AUTOSAR XML (schema 4-2-2)
package /ComponentTypes
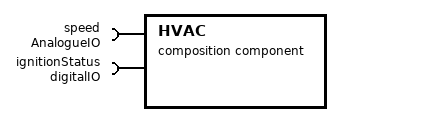
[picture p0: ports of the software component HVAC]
  composition sw component type HVAC
    require port speed: required-interface=AnalogueIO
    require port ignitionStatus: required-interface=digitalIO
    29 x component:
      SAFace: type=Switch
      SAFoot: type=Switch
      SAWindow: type=Switch
      SAHeatedDriverSeats: type=HeatedSeats
      SAHeatedPassengerSeats: type=HeatedSeats
      SAHotColdDriver: type=AirMixOut
      SAHotColdPassenger: type=AirMixOut
      SAFaceFoot: type=AirMixOut
      SAFaceVent: type=AirMixOut
      SABlowerMotorSpeed: type=AirBlowOut
      SAPassengerCurrentTempSet: type=CabinTempClosedLoop
      ECU: type=ECU
      SAOutsideTemp: type=Temp
      SADriverCabinTempSet: type=CabinTempClosedLoop
      SAAirBlower: type=AirBlow
      SAOutsideTempOutside: type=TempOut
      SAHeatedDriverSeatsOut: type=HeatedSeatsOut
      SAHeatedPassengerSeatOut: type=HeatedSeatsOut
      faceDir: type=SwitchOut
      windowDir: type=SwitchOut
      footDir: type=SwitchOut
      HotColdDriver: type=AirMixIn
      HotColdPassenger: type=AirMixIn
      FaceFoot: type=AirMixIn
      FaceVent: type=AirMixIn
      CabinClosedLoopIn: type=CabinTempClosedLoopAtomic
      CabinClosedLoopInDriver: type=CabinTempClosedLoopAtomic
      CabinClosedLoopInDriverSet: type=CabinTempClosedLoopAtomic
      CabinClosedLoopInPassenger: type=CabinTempClosedLoopAtomic
    delegate ECU.ignition <-> outer port ignitionStatus
    delegate ECU.speed <-> outer port speed
    connect SAOutsideTemp.temp -> ECU.outsideTemp
    connect ECU.tempOutside -> SAOutsideTempOutside.temp
    connect SAFoot.buttonSet -> ECU.footSet
    connect SAWindow.buttonSet -> ECU.windowSet
    connect SAHeatedDriverSeats.heatedSeatsOnOff -> ECU.heatedDriverSeatsOnOff
    connect SAFace.buttonSet -> ECU.faceSet
    connect SAHeatedPassengerSeats.heatedSeatsOnOff -> ECU.heatedPassengerSeatsOnOff
    connect ECU.hotColdDriver -> SAHotColdDriver.FlapSettingPercent
    connect ECU.FaceFoot -> SAFaceFoot.FlapSettingPercent
    connect ECU.HotColdPassenger -> SAHotColdPassenger.FlapSettingPercent
    connect ECU.FaceVent -> SAFaceVent.FlapSettingPercent
    connect ECU.PWMAirBlowOutput -> SABlowerMotorSpeed.pwmBlowerSpeedOut
    connect ECU.DriverSeatsOnOff -> SAHeatedDriverSeatsOut.heatedSeatsOnOff
    connect ECU.PassengerSeatsOnOff -> SAHeatedPassengerSeatOut.heatedSeatsOnOff
    connect ECU.faceDir -> faceDir.switchIn
    connect ECU.WindowDir -> windowDir.switchIn
    connect ECU.footDir -> footDir.switchIn
    connect HotColdDriver.FlapSettingPercent -> ECU.HotColdDriverIn
    connect HotColdPassenger.FlapSettingPercent -> ECU.HotColdPassengerIn
    connect FaceVent.FlapSettingPercent -> ECU.FaceVentIn
    connect FaceFoot.FlapSettingPercent -> ECU.FaceFootIn
    connect SAAirBlower.AirBlowIn -> ECU.PWMAirBlowIn
    connect CabinClosedLoopIn.tempObt -> ECU.PassengerTemp
    connect CabinClosedLoopInDriver.tempObt -> ECU.driverTemp
    connect ECU.PassengerTempOut -> SAPassengerCurrentTempSet.currentTempSet
    connect ECU.DriverTempOut -> SADriverCabinTempSet.currentTempSet
    connect CabinClosedLoopInDriverSet.tempObt -> ECU.driverTempSet
    connect CabinClosedLoopInPassenger.tempObt -> ECU.passengerTempSet
